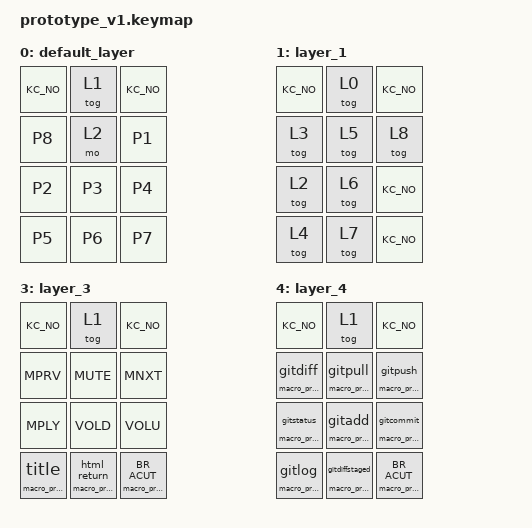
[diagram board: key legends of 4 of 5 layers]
/*
 * Copyright (c) 2020 The ZMK Contributors
 *
 * SPDX-License-Identifier: MIT
 */

#undef ZMK_BEHAVIORS_KEEP_ALL

#include <behaviors.dtsi>
#include <dt-bindings/zmk/keys.h>
#include <dt-bindings/zmk/bt.h>
#include <dt-bindings/zmk/layers.h>

/*
Ativando o Bluetooth: https://zmk.dev/docs/keymaps/behaviors/bluetooth
#include <dt-bindings/zmk/bt.h>
*/

/ {
    keymap {
        compatible = "zmk,keymap";

        default_layer {
            bindings = <
                KC_NO   &tog 1  KC_NO
                &kp P8  &mo 2   &kp P1
                &kp P2  &kp P3  &kp P4
                &kp P5  &kp P6  &kp P7
            >;
        };

        layer_1 {
            bindings = <
                KC_NO   &tog 0  KC_NO
                &tog 3  &tog 5  &tog 8
                &tog 2  &tog 6  KC_NO
                &tog 4  &tog 7  KC_NO
            >;
        };

        layer_2 {  /* Quantum */
            bindings = <
                KC_NO    &tog 1 KC_NO
                KC_NO    KC_NO KC_NO
                &boot    KC_NO KC_NO
                KC_NO    KC_NO KC_NO
            >;
        };

        layer_3 {  /* Media */
            bindings = <
                KC_NO     &tog 1  KC_NO
                &kp MPRV  &kp MUTE &kp MNXT
                &kp MPLY  &kp VOLD &kp VOLU
                &macro_press title  &macro_press html_return  &macro_press BR_ACUT
            >;
        };

        layer_4 {  /* GIT */
            bindings = <
                KC_NO      &tog 1  KC_NO
                &macro_press gitdiff   &macro_press gitpull   &macro_press gitpush
                &macro_press gitstatus &macro_press gitadd    &macro_press gitcommit
                &macro_press gitlog    &macro_press gitdiffstaged   &macro_press BR_ACUT
            >;
        };
};
